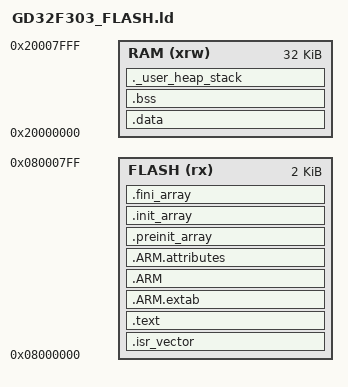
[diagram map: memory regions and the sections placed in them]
/* Entry Point */
ENTRY(Reset_Handler)

_Min_Stack_Size = 0x400;

/* Highest address of the user mode stack */
_estack = ORIGIN(RAM) + LENGTH(RAM);

/* Specify the memory areas */
MEMORY
{
  FLASH (rx)      : ORIGIN = 0x08000000, LENGTH = 2K
  RAM (xrw)       : ORIGIN = 0x20000000, LENGTH = 32K
}

/* Define output sections */
SECTIONS
{
  /* The startup code goes first into FLASH */
  .isr_vector :
  {
    . = ALIGN(4);
    KEEP(*(.isr_vector))
    . = ALIGN(4);
  } >FLASH

  /* The program code and other data goes into FLASH */
  .text :
  {
    . = ALIGN(4);
    *(.text)
    *(.text*)
    *(.rodata)
    *(.rodata*)
    *(.glue_7)
    *(.glue_7t)

    KEEP (*(.init))
    KEEP (*(.fini))

    . = ALIGN(4);
    _etext = .;
  } >FLASH

  .ARM.extab   : { *(.ARM.extab* .gnu.linkonce.armextab.*) } >FLASH
  .ARM : {
    __exidx_start = .;
    *(.ARM.exidx*)
    __exidx_end = .;
  } >FLASH

  .ARM.attributes : { *(.ARM.attributes) } > FLASH

  .preinit_array :
  {
    PROVIDE_HIDDEN (__preinit_array_start = .);
    KEEP (*(.preinit_array*))
    PROVIDE_HIDDEN (__preinit_array_end = .);
  } >FLASH
  .init_array :
  {
    PROVIDE_HIDDEN (__init_array_start = .);
    KEEP (*(SORT(.init_array.*)))
    KEEP (*(.init_array*))
    PROVIDE_HIDDEN (__init_array_end = .);
  } >FLASH
  .fini_array :
  {
    PROVIDE_HIDDEN (__fini_array_start = .);
    KEEP (*(SORT(.fini_array.*)))
    KEEP (*(.fini_array*))
    PROVIDE_HIDDEN (__fini_array_end = .);
  } >FLASH

  /* used by the startup to initialize data */
  _sidata = .;

  /* Initialized data sections goes into RAM, load LMA copy after code */
  .data : AT ( _sidata )
  {
    . = ALIGN(4);
    _sdata = .;
    *(.data)
    *(.data*)

    . = ALIGN(4);
    _edata = .;
  } >RAM

  /* Uninitialized data section */
  . = ALIGN(4);
  .bss :
  {
    _sbss = .;
    __bss_start__ = _sbss;
    *(.bss)
    *(.bss*)
    *(COMMON)

    . = ALIGN(4);
    _ebss = .;
    __bss_end__ = _ebss;
  } >RAM

  PROVIDE ( end = _ebss );
  PROVIDE ( _end = _ebss );

  /* User_heap_stack section */
  ._user_heap_stack :
  {
    . = ALIGN(4);
    . = . + _Min_Stack_Size;
    . = ALIGN(4);
  } >RAM

  /* Remove information from the standard libraries */
  /DISCARD/ :
  {
    libc.a ( * )
    libm.a ( * )
    libgcc.a ( * )
  }
}
